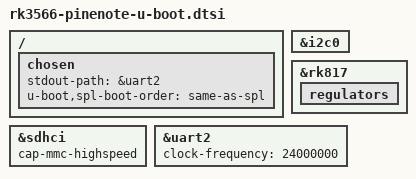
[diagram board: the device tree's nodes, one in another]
// SPDX-License-Identifier: (GPL-2.0+ OR MIT)
/*
 * Copyright (c) 2023 Collabora Ltd.
 */

#include "rk356x-u-boot.dtsi"

/ {
	chosen {
		stdout-path = &uart2;
		u-boot,spl-boot-order = "same-as-spl", &sdhci;
	};
};

&i2c0 {
	bootph-pre-ram;
};

&rk817 {
	bootph-pre-ram;

	regulators {
		bootph-pre-ram;
	};
};

&sdhci {
	cap-mmc-highspeed;
};

&uart2 {
	bootph-all;
	clock-frequency = <24000000>;
	status = "okay";
};
